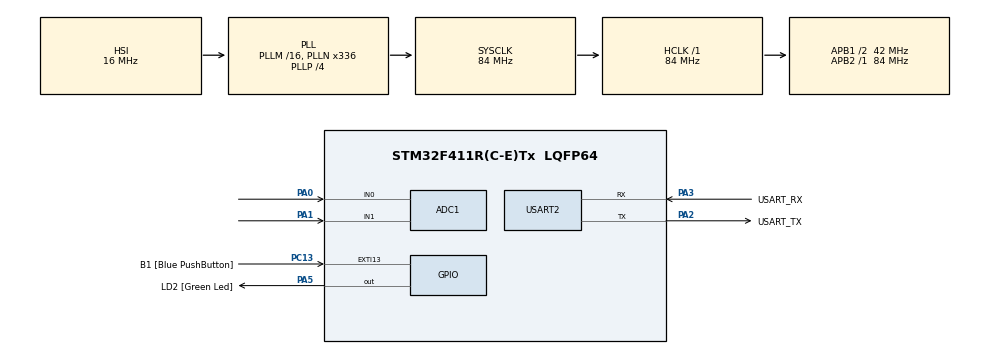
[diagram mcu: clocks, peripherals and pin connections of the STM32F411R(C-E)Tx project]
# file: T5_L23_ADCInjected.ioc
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ADC1.Channel-0\#ChannelRegularConversion=ADC_CHANNEL_0
ADC1.Channel-2\#ChannelInjectedConversion=ADC_CHANNEL_1
ADC1.ContinuousConvMode=ENABLE
ADC1.DMAContinuousRequests=ENABLE
ADC1.InjNumberOfConversion=1
ADC1.InjectedOffset-2\#ChannelInjectedConversion=0
ADC1.InjectedRank-2\#ChannelInjectedConversion=1
ADC1.NbrOfConversion=1
ADC1.NbrOfConversionFlag=1
ADC1.Rank-0\#ChannelRegularConversion=1
ADC1.SamplingTime-0\#ChannelRegularConversion=ADC_SAMPLETIME_3CYCLES
ADC1.SamplingTime-2\#ChannelInjectedConversion=ADC_SAMPLETIME_480CYCLES
ADC1.master=1
Dma.ADC1.0.Direction=DMA_PERIPH_TO_MEMORY
Dma.ADC1.0.FIFOMode=DMA_FIFOMODE_DISABLE
Dma.ADC1.0.Instance=DMA2_Stream0
Dma.ADC1.0.MemDataAlignment=DMA_MDATAALIGN_HALFWORD
Dma.ADC1.0.MemInc=DMA_MINC_ENABLE
Dma.ADC1.0.Mode=DMA_CIRCULAR
Dma.ADC1.0.PeriphDataAlignment=DMA_PDATAALIGN_HALFWORD
Dma.ADC1.0.PeriphInc=DMA_PINC_DISABLE
Dma.ADC1.0.Priority=DMA_PRIORITY_LOW
Dma.Request0=ADC1
Mcu.Family=STM32F4
Mcu.Name=STM32F411R(C-E)Tx
Mcu.Package=LQFP64
NVIC.ADC_IRQn=true\:0\:0\:false\:false\:true\:true\:true
NVIC.DMA2_Stream0_IRQn=true\:0\:0\:false\:false\:true\:false\:true
NVIC.PriorityGroup=NVIC_PRIORITYGROUP_0
PA0-WKUP.Signal=ADCx_IN0
PA1.Signal=ADCx_IN1
PA13.GPIO_Label=TMS
PA13.Mode=Serial_Wire
PA13.Signal=SYS_JTMS-SWDIO
PA14.GPIO_Label=TCK
PA14.Mode=Serial_Wire
PA14.Signal=SYS_JTCK-SWCLK
PA2.GPIO_Label=USART_TX
PA2.Mode=Asynchronous
PA2.Signal=USART2_TX
PA3.GPIO_Label=USART_RX
PA3.Mode=Asynchronous
PA3.Signal=USART2_RX
PA5.GPIO_Label=LD2 [Green Led]
PA5.Signal=GPIO_Output
PB3.GPIO_Label=SWO
PB3.Signal=SYS_JTDO-SWO
PC13-ANTI_TAMP.GPIO_Label=B1 [Blue PushButton]
PC13-ANTI_TAMP.GPIO_ModeDefaultEXTI=GPIO_MODE_IT_FALLING
PC13-ANTI_TAMP.Signal=GPXTI13
PC14-OSC32_IN.Mode=LSE-External-Oscillator
PC14-OSC32_IN.Signal=RCC_OSC32_IN
PC15-OSC32_OUT.Mode=LSE-External-Oscillator
PC15-OSC32_OUT.Signal=RCC_OSC32_OUT
PH0\ -\ OSC_IN.Mode=HSE-External-Clock-Source
PH0\ -\ OSC_IN.Signal=RCC_OSC_IN
PH1\ -\ OSC_OUT.Mode=HSE-External-Clock-Source
PH1\ -\ OSC_OUT.Signal=RCC_OSC_OUT
ProjectManager.HeapSize=0x200
ProjectManager.StackSize=0x400
ProjectManager.TargetToolchain=STM32CubeIDE
RCC.48MHZClocksFreq_Value=84000000
RCC.AHBFreq_Value=84000000
RCC.APB1CLKDivider=RCC_HCLK_DIV2
RCC.APB1Freq_Value=42000000
RCC.APB1TimFreq_Value=84000000
RCC.APB2Freq_Value=84000000
RCC.APB2TimFreq_Value=84000000
RCC.CortexFreq_Value=84000000
RCC.FLatency-AdvancedSettings=FLASH_LATENCY_2
RCC.HCLKFreq_Value=84000000
RCC.HSE_VALUE=8000000
RCC.HSI_VALUE=16000000
RCC.PLLN=336
RCC.PLLP=RCC_PLLP_DIV4
RCC.SYSCLKFreq_VALUE=84000000
RCC.SYSCLKSource=RCC_SYSCLKSOURCE_PLLCLK
RCC.VCOOutputFreq_Value=336000000
SH.ADCx_IN0.0=ADC1_IN0,IN0
SH.ADCx_IN1.0=ADC1_IN1,IN1
USART2.VirtualMode=VM_ASYNC
board=NUCLEO-F411RE

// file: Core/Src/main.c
/* USER CODE BEGIN Header */
/**
  ******************************************************************************
  * @file           : main.c
  * @brief          : Main program body
  ******************************************************************************
  * @attention
  *
  * <h2><center>&copy; Copyright (c) 2021 STMicroelectronics.
  * All rights reserved.</center></h2>
  *
  * This software component is licensed by ST under BSD 3-Clause license,
  * the "License"; You may not use this file except in compliance with the
  * License. You may obtain a copy of the License at:
  *                        opensource.org/licenses/BSD-3-Clause
  *
  ******************************************************************************
  */
/* USER CODE END Header */
#include "main.h"
#include "adc.h"
#include "dma.h"
#include "usart.h"
#include "gpio.h"

/* USER CODE BEGIN PV */
uint16_t AdcRegular;
uint16_t AdcInjected;
/* USER CODE END PV */

void SystemClock_Config(void);

int main(void)
{

  /* MCU Configuration--------------------------------------------------------*/

  /* Reset of all peripherals, Initializes the Flash interface and the Systick. */
  HAL_Init();

  /* Configure the system clock */
  SystemClock_Config();

  /* Initialize all configured peripherals */
  MX_GPIO_Init();
  MX_DMA_Init();
  MX_USART2_UART_Init();
  MX_ADC1_Init();
  /* USER CODE BEGIN 2 */
  HAL_ADCEx_InjectedStart_IT(&hadc1);
  HAL_ADC_Start_DMA(&hadc1, (uint32_t*)&AdcRegular, 1);
  /* USER CODE END 2 */

  /* Infinite loop */
  while (1)
  {

  }
}

void SystemClock_Config(void)
{
  RCC_OscInitTypeDef RCC_OscInitStruct = {0};
  RCC_ClkInitTypeDef RCC_ClkInitStruct = {0};

  /** Configure the main internal regulator output voltage
  */
  __HAL_RCC_PWR_CLK_ENABLE();
  __HAL_PWR_VOLTAGESCALING_CONFIG(PWR_REGULATOR_VOLTAGE_SCALE1);
  /** Initializes the RCC Oscillators according to the specified parameters
  * in the RCC_OscInitTypeDef structure.
  */
  RCC_OscInitStruct.OscillatorType = RCC_OSCILLATORTYPE_HSI;
  RCC_OscInitStruct.HSIState = RCC_HSI_ON;
  RCC_OscInitStruct.HSICalibrationValue = RCC_HSICALIBRATION_DEFAULT;
  RCC_OscInitStruct.PLL.PLLState = RCC_PLL_ON;
  RCC_OscInitStruct.PLL.PLLSource = RCC_PLLSOURCE_HSI;
  RCC_OscInitStruct.PLL.PLLM = 16;
  RCC_OscInitStruct.PLL.PLLN = 336;
  RCC_OscInitStruct.PLL.PLLP = RCC_PLLP_DIV4;
  RCC_OscInitStruct.PLL.PLLQ = 4;
  if (HAL_RCC_OscConfig(&RCC_OscInitStruct) != HAL_OK)
  {
    Error_Handler();
  }
  /** Initializes the CPU, AHB and APB buses clocks
  */
  RCC_ClkInitStruct.ClockType = RCC_CLOCKTYPE_HCLK|RCC_CLOCKTYPE_SYSCLK
                              |RCC_CLOCKTYPE_PCLK1|RCC_CLOCKTYPE_PCLK2;
  RCC_ClkInitStruct.SYSCLKSource = RCC_SYSCLKSOURCE_PLLCLK;
  RCC_ClkInitStruct.AHBCLKDivider = RCC_SYSCLK_DIV1;
  RCC_ClkInitStruct.APB1CLKDivider = RCC_HCLK_DIV2;
  RCC_ClkInitStruct.APB2CLKDivider = RCC_HCLK_DIV1;

  if (HAL_RCC_ClockConfig(&RCC_ClkInitStruct, FLASH_LATENCY_2) != HAL_OK)
  {
    Error_Handler();
  }
}

/* USER CODE BEGIN 4 */
void HAL_ADCEx_InjectedConvCpltCallback(ADC_HandleTypeDef* hadc)
{
	if(hadc->Instance == ADC1)
	{
		AdcInjected = HAL_ADCEx_InjectedGetValue(hadc, ADC_INJECTED_RANK_1);
		HAL_ADCEx_InjectedStart_IT(&hadc1);
	}
}
/* USER CODE END 4 */

void Error_Handler(void)
{
  __disable_irq();
  while (1)
  {
  }
}

/************************ (C) COPYRIGHT STMicroelectronics *****END OF FILE****/
